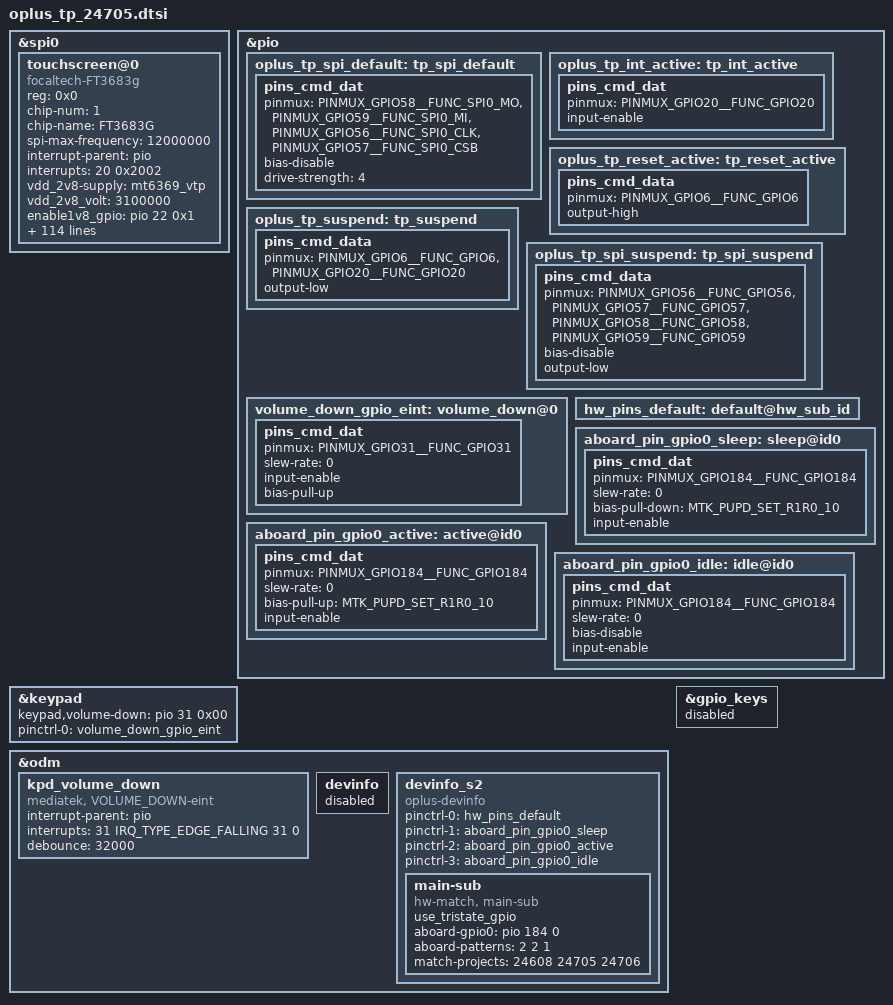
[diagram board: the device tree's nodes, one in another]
&spi0 {
	status = "okay";
	#address-cells = <1>;
	#size-cells = <0>;
	touchscreen@0{
		compatible = "focaltech-FT3683g";
		reg = <0x0>;
		chip-num = <1>;
		chip-name = "FT3683G";
		status = "okay";
		spi-max-frequency = <12000000>;
		/* Interrupt && Irq-gpio */
		interrupt-parent = <&pio>;
		interrupts = <20 0x2002>;

		/* Power Config */
		vdd_2v8-supply  = <&mt6369_vtp>;
		vdd_2v8_volt = <3100000>;
		enable1v8_gpio = <&pio 22 0x1>;

		/* Other HW Resource */
		irq-gpio = <&pio 20 0x2002>;
		reset-gpio = <&pio 6 0x1>;

		pinctrl-names = "default",  "sleep";
		pinctrl-0 = <&oplus_tp_int_active &oplus_tp_reset_active &oplus_tp_spi_default>;
		pinctrl-1 = <&oplus_tp_suspend &oplus_tp_spi_suspend>;

		project_id = <24706>;
		touchpanel,max-num-support = <10>;
		touchpanel,tx-rx-num = <18 40>;
		earsense,tx-rx-num = <17 18>;
		touchpanel,panel-coords = <17280 38272>;
		touchpanel,display-coords = <1080 2392>;
		touchpanel,touchmajor-limit = <128 216>;
		touchpanel,smooth-level = <0 110 115 120 140 155>;
		touchpanel,smooth-level-charging = <0 110 115 120 140 155>;
		touchpanel,sensitive-level = <0 19 16 12 11 10>;
		touchpanel,tp-index = <0>;
		touchpanel,high-frame-rate-time = <60>;
		touchpanel,single-optimized-time = <8>;

		vid_len = <2>;
		firmware_name = "A865FT3";
		panel_type = <7>;
		platform_support_project = <24608 24705 24706>;
		platform_support_project_dir = <24706 24706 24706>;
		platform_support_project_commandline = "nt37703a_fhdp_dsi_vdo_120hz_dphy_lcm_drv";

		prevention,curved_screen_V2;
		prevention,grip_disable_level = <6>;
		prevention,updelay_time_ms = <30>;
		prevention,makeup_cnt_weight = <4 1 2 2 2>;
		prevention,large_corner_range = <1920 4800>;
		prevention,large_corner_judge_condition = <500 300 1600 6 6>;
		prevention,trx_reject_condition = <8 7 7>;
		prevention,trx_strict_reject_condition = <7 6 6>;
		prevention,large_judge_time_ms = <500 50 30>;
		prevention,large_exit_condition = <15 12 2>;
		prevention,single_channel_width = <256 256>;
		prevention,normal_tap_condition = <10 300>;
		prevention,long_edge_condition = <230 100 180 80>;
		prevention,long_strict_edge_condition = <170 80>;
		prevention,long_fingerhold_condition = <50 6 4 4>;
		prevention,short_edge_condition = <230 100 180 80>;
		prevention,short_strict_edge_condition = <160 60>;
		prevention,large_strict_exit_condition = <5 5>;
		prevention,top_corner_config = <800 2400 720>;
		prevention,edge_swipe_config = <480 1600>;

		prevention,curved_screen_V4;
		prevention,long_eliminate_point_type = <2 17280 13280 420 38592 300 1>;
		prevention,long_fingerhold_condition2 = <1120 3200 0 0>;
		prevention,top_corner_config2 =<3 80 420 2400 0>;
		prevention,hor_long_top_corner_config =<480 3200 0 0>;
		prevention,top_middle_config =<17280 1600 1600 0>;
		prevention,corner_eliminate_point_type =<0 1920 3200 1>;
		prevention,finger_hold_differ_size = <1 0 720 300>;
		prevention,finger_hold_max_rx_exit_distance = <5 700 3400>;
		prevention,max_rx_exit_distance = <1 5 18 700 2800>;
		prevention,dynamic_finger_hold_exit_distance = <1 580 3400 780>;
		prevention,edge_sliding_matched_support = <1 250 3 0>;

		//grip v4.2 reclining mode
		prevention,reclining_mode_support = <1>;
		prevention,long_eliminate_point_type_recli = <2 17280 13280 420 38592 200 1>;
		prevention,finger_hold_differ_size_recli = <1 0 720 300>;
		prevention,finger_hold_max_rx_exit_distance_recli = <5 700 3400>;
		prevention,max_rx_exit_distance_recli = <1 5 90 700 2800>;
		prevention,dynamic_finger_hold_exit_distance_recli = <1 580 3400 780>;
		prevention,edge_sliding_matched_support_recli = <1 200 3 0>;
		prevention,long_edge_condition_recli = <120 100 150 100>;

		/* SW Support Feature Control */
		health_monitor_v2_support;
		disable_suspend_irq_handler_support;
		black_gesture_support;
		charger_pump_support;
		lcd_tp_refresh_support;
		fw_update_app_support;
		smart_gesture_support;
		game_switch_support;
		report_flow_unlock_support;
		kernel_grip_support;
		fingerprint_underscreen_support;
		pressure_report_support;
		auto_test_force_pass_support;
		snr_read_support;
		//high_resolution_support;
		screenoff_fingerprint_info_support;
		irq_need_dev_resume_ok;
		sportify_aod_gesture_support;
		black_gesture_indep_support;
		thermal_detect_support;
		exception_upload_support;
		tp_data_record_support;
		palm_to_sleep_support;
		diaphragm_touch_support;
		report_rate_white_list_support;
		esd_handle_support;
		/*
		*Virtual Key Config:
		*1:touchpanel,button-type: <virtualkey_type  supportted_button-map>
		*virtualkey_type:
		*Type 1: using board_properties
		*Type 2: using same IC (button zone&& touch zone are seprate)
		*Type 3: using diffrent IC (button zone&& touch zone are seprate)
		*Type 4: No need of virtual key process
		*supportted_button-map:select|menu|home|back
		*
		*2:touchpanel,button-map
		*type (X1,Y1)(X2,Y2)(X3,Y3)(Width_X,Hight_Y)--Only when button-type is 0
		*/
		touchpanel,button-type = <4>;
		touchpanel.button-TRx = <0 0>;
	};
};

&pio {
	oplus_tp_spi_default: tp_spi_default {
		pins_cmd_dat {
		pinmux = <PINMUX_GPIO58__FUNC_SPI0_MO>,
				<PINMUX_GPIO59__FUNC_SPI0_MI>,
				<PINMUX_GPIO56__FUNC_SPI0_CLK>,
				<PINMUX_GPIO57__FUNC_SPI0_CSB>;
			bias-disable;
			drive-strength = <4>;
		};
	};
	oplus_tp_int_active: tp_int_active {
		pins_cmd_dat {
			pinmux = <PINMUX_GPIO20__FUNC_GPIO20>;
			input-enable;
		};
	};
	oplus_tp_reset_active: tp_reset_active {
		pins_cmd_data {
			pinmux = <PINMUX_GPIO6__FUNC_GPIO6>;
			output-high;
		};
	};
	oplus_tp_suspend: tp_suspend {
		pins_cmd_data {
			pinmux = <PINMUX_GPIO6__FUNC_GPIO6>,
					<PINMUX_GPIO20__FUNC_GPIO20>;
			output-low;
		};
	};
	oplus_tp_spi_suspend: tp_spi_suspend {
		pins_cmd_data {
			pinmux = <PINMUX_GPIO56__FUNC_GPIO56>,
					<PINMUX_GPIO57__FUNC_GPIO57>,
					<PINMUX_GPIO58__FUNC_GPIO58>,
					<PINMUX_GPIO59__FUNC_GPIO59>;
			bias-disable;
			output-low;
		};
	};
};
&keypad {
		keypad,volume-down = <&pio 31 0x00>;
		pinctrl-names = "volume_down_as_int";
		pinctrl-0 = <&volume_down_gpio_eint>;
		status = "okay";
};

&pio {
        volume_down_gpio_eint:volume_down@0{
                pins_cmd_dat {
                        pinmux = <PINMUX_GPIO31__FUNC_GPIO31>;
                        slew-rate = <0>;  /*direction 0:in, 1:out*/
                        input-enable;
                        bias-pull-up;
                };
        };
};

&odm {
        kpd_volume_down:kpd_volume_down {
                compatible = "mediatek, VOLUME_DOWN-eint";
                interrupt-parent = <&pio>;
                interrupts = <31 IRQ_TYPE_EDGE_FALLING 31 0>;
                debounce = <32000>;
                status = "okay";
        };
};

&odm {
	devinfo {
		status = "disabled";
	};

	devinfo_s2 {
		compatible = "oplus-devinfo";

		pinctrl-names = "default", "aboard_gpio0_sleep", "aboard_gpio0_active", "aboard_gpio0_idle";
		pinctrl-0 = <&hw_pins_default>;
		pinctrl-1 = <&aboard_pin_gpio0_sleep>;
		pinctrl-2 = <&aboard_pin_gpio0_active>;
		pinctrl-3 = <&aboard_pin_gpio0_idle>;

		main-sub {
			compatible = "hw-match, main-sub";
			use_tristate_gpio;
			aboard-gpio0 = <&pio 184 0>;
			aboard-patterns = <2 2 1>;	/*0[high-resistance] 1[pull-down] 2[pull-up]*/
			/*main board*/
			match-projects = <24608 24705 24706>;
		};
	};
};

&pio{
	hw_pins_default:default@hw_sub_id {
	};

	aboard_pin_gpio0_sleep:sleep@id0 {
		pins_cmd_dat {
			pinmux = <PINMUX_GPIO184__FUNC_GPIO184>;
			slew-rate = <0>;
			bias-pull-down = <MTK_PUPD_SET_R1R0_10>;
			input-enable;
		};
	};

	aboard_pin_gpio0_active:active@id0 {
		pins_cmd_dat {
			pinmux = <PINMUX_GPIO184__FUNC_GPIO184>;
			slew-rate = <0>;
			bias-pull-up = <MTK_PUPD_SET_R1R0_10>;
			input-enable;
		};
	};

	aboard_pin_gpio0_idle:idle@id0 {
		pins_cmd_dat {
			pinmux = <PINMUX_GPIO184__FUNC_GPIO184>;
			slew-rate = <0>;
			bias-disable;
			input-enable;
		};
	};
};

&gpio_keys {
	status = "disabled";
};
